# MCU_CTRL_MMR0_CFG0 register map
Vendor: Texas Instruments
Registers are 32-bit, read-write, reset 0x0 unless marked. A register's access mark holds for its fields unless they carry their own. Offsets are as the file gives them; [hi:lo] are bit positions; lines under a group give offsets from that group; {n}, {i} and the like mark numbered series.

## MCU_CTRL_MMR0_CFG0 (part 2 of 3)
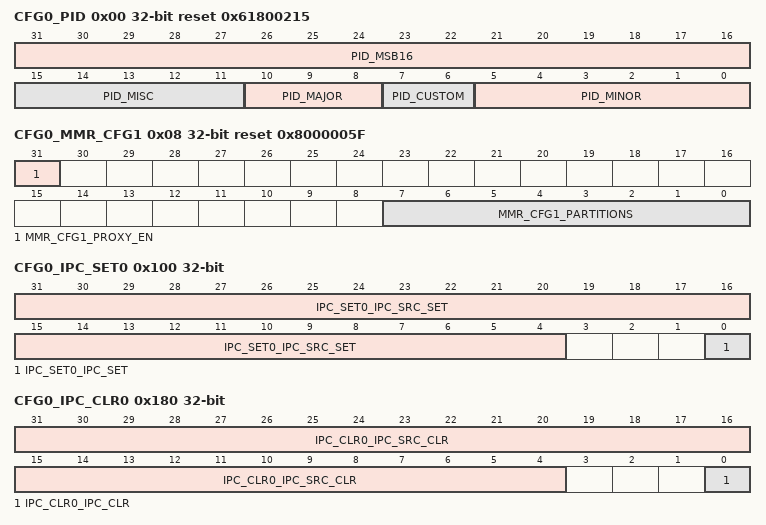
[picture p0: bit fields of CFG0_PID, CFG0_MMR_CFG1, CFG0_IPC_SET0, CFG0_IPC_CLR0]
0x00 CFG0_PID ro reset 0x61800215
  [31:16] PID_MSB16, [15:11] PID_MISC, [10:8] PID_MAJOR, [7:6] PID_CUSTOM, [5:0] PID_MINOR
0x08 CFG0_MMR_CFG1 ro reset 0x8000005F
  [31] MMR_CFG1_PROXY_EN — Proxy addressing activated
  [7:0] MMR_CFG1_PARTITIONS — Indicates present partitions
0x100 CFG0_IPC_SET0 access not given
  [31:4] IPC_SET0_IPC_SRC_SET — Read returns 0 Write: 0 - No effect 1 - Sets both corresponding IPC_CLR and the IPC_SET bits (access R/W1TS)
  [0] IPC_SET0_IPC_SET — Read returns 0 Write: 0 - No effect 1 - Sets both corresponding IPC_CLR and the IPC_SET bits (access R/W1TS)
0x180 CFG0_IPC_CLR0 access not given
  [31:4] IPC_CLR0_IPC_SRC_CLR — Read returns current value Write: 0 - No effect 1 - Clears both corresponding IPC_CLR and the IPC_SET bits (access R/W1TC)
  [0] IPC_CLR0_IPC_CLR — Read returns current value Write: 0 - No effect 1 - Clears both corresponding IPC_CLR and the IPC_SET bits (access R/W1TC)
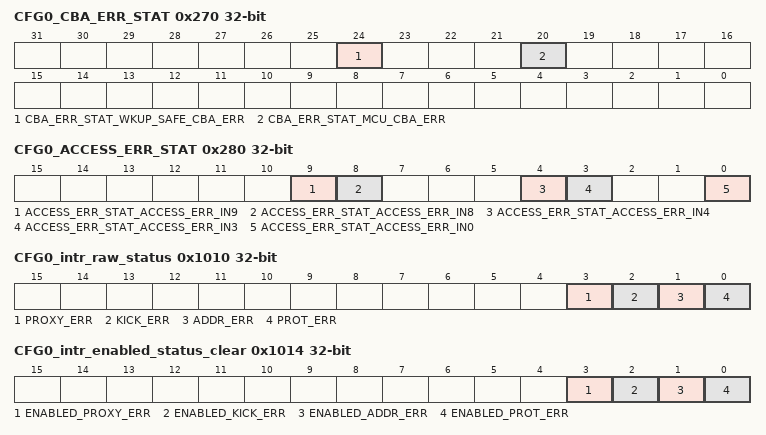
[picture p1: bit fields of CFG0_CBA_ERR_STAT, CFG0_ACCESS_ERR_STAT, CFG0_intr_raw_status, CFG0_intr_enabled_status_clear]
0x270 CFG0_CBA_ERR_STAT ro
  [24] CBA_ERR_STAT_WKUP_SAFE_CBA_ERR — Access Error from Wkup Safe CBASS Field values (others are reserved): 1'b0 - INACTIVE 1'b1 - ACTIVE
  [20] CBA_ERR_STAT_MCU_CBA_ERR — Access Error from MCU CBASS Field values (others are reserved): 1'b0 - INACTIVE 1'b1 - ACTIVE
0x280 CFG0_ACCESS_ERR_STAT ro
  [9] ACCESS_ERR_STAT_ACCESS_ERR_IN9 — Access Error From MCU_PADCFG_CTRL0 MMR Field values (others are reserved): 1'b0 - INACTIVE 1'b1 - ACTIVE
  [8] ACCESS_ERR_STAT_ACCESS_ERR_IN8 — Access Error From WKUP_CTRL_MMR1 Field values (others are reserved): 1'b0 - INACTIVE 1'b1 - ACTIVE
  [4] ACCESS_ERR_STAT_ACCESS_ERR_IN4 — Access Error From PADCFG_CTRL0 MMR Field values (others are reserved): 1'b0 - INACTIVE 1'b1 - ACTIVE
  [3] ACCESS_ERR_STAT_ACCESS_ERR_IN3 — Access Error From CTRL_MMR0 Field values (others are reserved): 1'b0 - INACTIVE 1'b1 - ACTIVE
  [0] ACCESS_ERR_STAT_ACCESS_ERR_IN0 — Access Error From WKUP_CTRL_MMR0 Field values (others are reserved): 1'b0 - INACTIVE 1'b1 - ACTIVE
{0x1008+0x4000*i} CFG0_LOCK{i}_KICK0 (i=0..4)
  [31:0] LOCK{i}_KICK0 — - KICK0 component
{0x100C+0x4000*i} CFG0_LOCK{i}_KICK1 (i=0..4)
  [31:0] LOCK{i}_KICK1 — - KICK1 component
0x1010 CFG0_intr_raw_status access not given
  [3] PROXY_ERR — Proxy0 access violation error. Raw status is read. Write a 1 to set the status. Writing a 0 has no effect. (access R/W1TS)
  [2] KICK_ERR — Kick access violation error. Raw status is read. Write a 1 to set the status. Writing a 0 has no effect. (access R/W1TS)
  [1] ADDR_ERR — Addressing violation error. Raw status is read. Write a 1 to set the status. Writing a 0 has no effect. (access R/W1TS)
  [0] PROT_ERR — Protection violation error. Raw status is read. Write a 1 to set the status. Writing a 0 has no effect. (access R/W1TS)
0x1014 CFG0_intr_enabled_status_clear access not given
  [3] ENABLED_PROXY_ERR — Proxy0 access violation error. Enabled status is read. Write a 1 to clear the status. Writing a 0 has no effect. (access R/W1TC)
  [2] ENABLED_KICK_ERR — Kick access violation error. Enabled status is read. Write a 1 to clear the status. Writing a 0 has no effect. (access R/W1TC)
  [1] ENABLED_ADDR_ERR — Addressing violation error. Enabled status is read. Write a 1 to clear the status. Writing a 0 has no effect. (access R/W1TC)
  [0] ENABLED_PROT_ERR — Protection violation error. Enabled status is read. Write a 1 to clear the status. Writing a 0 has no effect. (access R/W1TC)
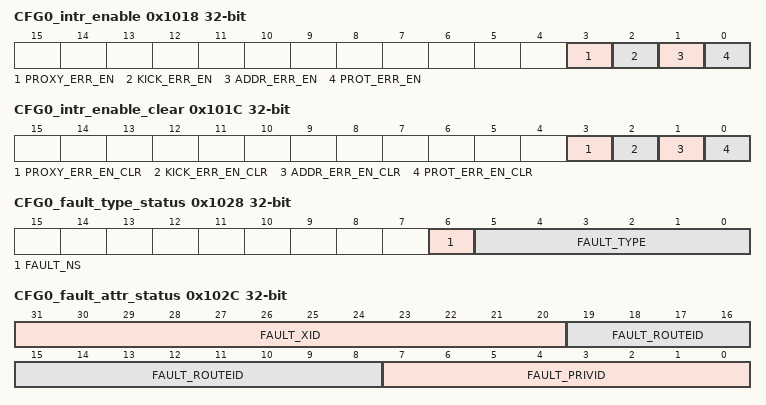
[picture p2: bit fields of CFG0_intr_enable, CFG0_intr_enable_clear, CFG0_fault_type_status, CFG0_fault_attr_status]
0x1018 CFG0_intr_enable access not given
  [3] PROXY_ERR_EN — Proxy0 access violation error enable. Write a 1 to set the enable. Writing a 0 has no effect. (access R/W1TS)
  [2] KICK_ERR_EN — Kick access violation error enable. Write a 1 to set the enable. Writing a 0 has no effect. (access R/W1TS)
  [1] ADDR_ERR_EN — Addressing violation error enable. Write a 1 to set the enable. Writing a 0 has no effect. (access R/W1TS)
  [0] PROT_ERR_EN — Protection violation error enable. Write a 1 to set the enable. Writing a 0 has no effect. (access R/W1TS)
0x101C CFG0_intr_enable_clear access not given
  [3] PROXY_ERR_EN_CLR — Proxy0 access violation error enable clear. Write a 1 to clear the enable. Writing a 0 has no effect. (access R/W1TC)
  [2] KICK_ERR_EN_CLR — Kick access violation error enable clear. Write a 1 to clear the enable. Writing a 0 has no effect. (access R/W1TC)
  [1] ADDR_ERR_EN_CLR — Addressing violation error enable clear. Write a 1 to clear the enable. Writing a 0 has no effect. (access R/W1TC)
  [0] PROT_ERR_EN_CLR — Protection violation error enable clear. Write a 1 to clear the enable. Writing a 0 has no effect. (access R/W1TC)
0x1020 CFG0_eoi
  [7:0] EOI_VECTOR — EOI vector value. Write this with interrupt distribution value in the chip.
0x1024 CFG0_fault_address ro
  [31:0] FAULT_ADDR — Fault Address.
0x1028 CFG0_fault_type_status ro
  [6] FAULT_NS — Non-secure access.
  [5:0] FAULT_TYPE — Fault Type 10_0000 = Supervisor read fault - priv = 1 dir = 1 dtype != 1 01_0000 = Supervisor write fault - priv = 1 dir = 0 00_1000 = Supervisor execute fault - priv = 1 dir = 1 dtype = 1 00_0100 = User read fault - priv = 0 dir = 1 dtype = 1 00_0010 = User write fault - priv = 0 dir = 0 00_0001 = User execute fault - priv = 0 dir = 1 dtype = 1 00_0000 = No fault
0x102C CFG0_fault_attr_status ro
  [31:20] FAULT_XID — XID.
  [19:8] FAULT_ROUTEID — Route ID.
  [7:0] FAULT_PRIVID — Privilege ID.
0x1030 CFG0_fault_clear wo
  [0] FAULT_CLR — Fault clear. Writing a 1 clears the current fault. Writing a 0 has no effect.
{0x1100+4i} CFG0_CLAIMREG_P0_R{i}_READONLY ro (i=0..5)
  [31:0] CLAIMREG_P0_R{i}_READONLY — Claim bits for Partition 0
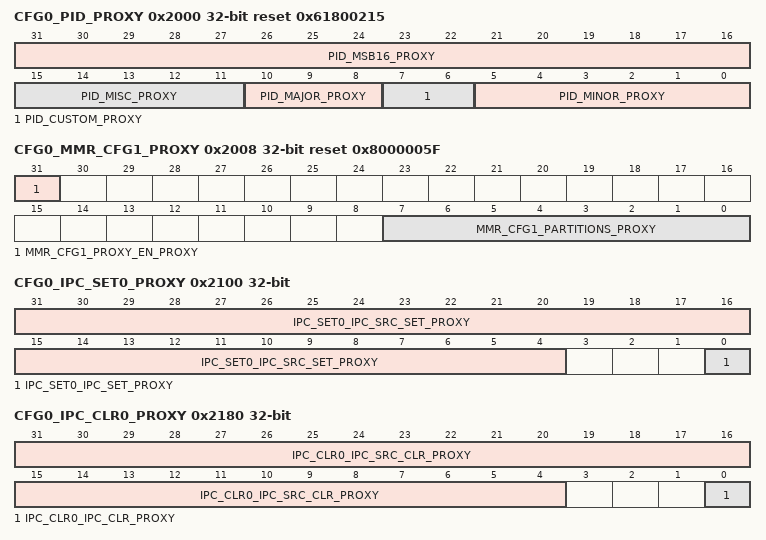
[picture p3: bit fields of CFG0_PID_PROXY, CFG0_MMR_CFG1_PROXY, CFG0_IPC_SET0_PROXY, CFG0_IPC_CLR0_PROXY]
0x2000 CFG0_PID_PROXY ro reset 0x61800215
  [31:16] PID_MSB16_PROXY, [15:11] PID_MISC_PROXY, [10:8] PID_MAJOR_PROXY, [7:6] PID_CUSTOM_PROXY, [5:0] PID_MINOR_PROXY
0x2008 CFG0_MMR_CFG1_PROXY ro reset 0x8000005F
  [31] MMR_CFG1_PROXY_EN_PROXY — Proxy addressing activated
  [7:0] MMR_CFG1_PARTITIONS_PROXY — Indicates present partitions
0x2100 CFG0_IPC_SET0_PROXY access not given
  [31:4] IPC_SET0_IPC_SRC_SET_PROXY — Read returns 0 Write: 0 - No effect 1 - Sets both corresponding IPC_CLR and the IPC_SET bits (access R/W1TS)
  [0] IPC_SET0_IPC_SET_PROXY — Read returns 0 Write: 0 - No effect 1 - Sets both corresponding IPC_CLR and the IPC_SET bits (access R/W1TS)
0x2180 CFG0_IPC_CLR0_PROXY access not given
  [31:4] IPC_CLR0_IPC_SRC_CLR_PROXY — Read returns current value Write: 0 - No effect 1 - Clears both corresponding IPC_CLR and the IPC_SET bits (access R/W1TC)
  [0] IPC_CLR0_IPC_CLR_PROXY — Read returns current value Write: 0 - No effect 1 - Clears both corresponding IPC_CLR and the IPC_SET bits (access R/W1TC)
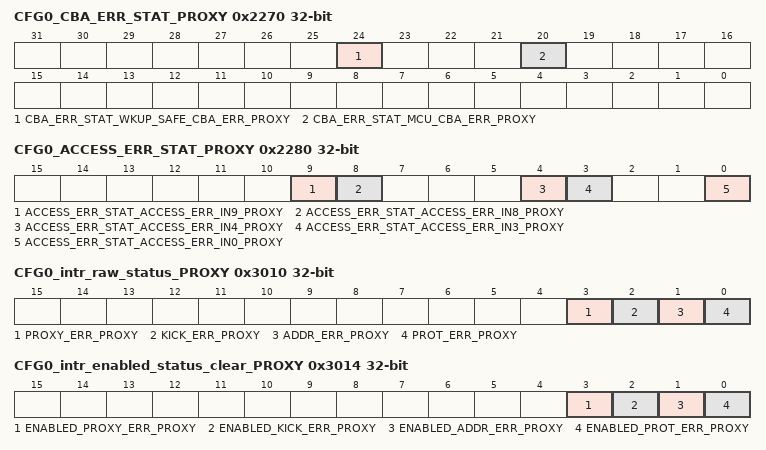
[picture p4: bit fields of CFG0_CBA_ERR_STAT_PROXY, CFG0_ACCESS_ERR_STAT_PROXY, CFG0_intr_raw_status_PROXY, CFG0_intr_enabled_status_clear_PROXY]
0x2270 CFG0_CBA_ERR_STAT_PROXY ro
  [24] CBA_ERR_STAT_WKUP_SAFE_CBA_ERR_PROXY — Access Error from Wkup Safe CBASS Field values (others are reserved): 1'b0 - INACTIVE 1'b1 - ACTIVE
  [20] CBA_ERR_STAT_MCU_CBA_ERR_PROXY — Access Error from MCU CBASS Field values (others are reserved): 1'b0 - INACTIVE 1'b1 - ACTIVE
0x2280 CFG0_ACCESS_ERR_STAT_PROXY ro
  [9] ACCESS_ERR_STAT_ACCESS_ERR_IN9_PROXY — Access Error From MCU_PADCFG_CTRL0 MMR Field values (others are reserved): 1'b0 - INACTIVE 1'b1 - ACTIVE
  [8] ACCESS_ERR_STAT_ACCESS_ERR_IN8_PROXY — Access Error From WKUP_CTRL_MMR1 Field values (others are reserved): 1'b0 - INACTIVE 1'b1 - ACTIVE
  [4] ACCESS_ERR_STAT_ACCESS_ERR_IN4_PROXY — Access Error From PADCFG_CTRL0 MMR Field values (others are reserved): 1'b0 - INACTIVE 1'b1 - ACTIVE
  [3] ACCESS_ERR_STAT_ACCESS_ERR_IN3_PROXY — Access Error From CTRL_MMR0 Field values (others are reserved): 1'b0 - INACTIVE 1'b1 - ACTIVE
  [0] ACCESS_ERR_STAT_ACCESS_ERR_IN0_PROXY — Access Error From WKUP_CTRL_MMR0 Field values (others are reserved): 1'b0 - INACTIVE 1'b1 - ACTIVE
{0x3008+0x4000*i} CFG0_LOCK{i}_KICK0_PROXY (i=0..4)
  [31:0] LOCK{i}_KICK0_PROXY — - KICK0 component
{0x300C+0x4000*i} CFG0_LOCK{i}_KICK1_PROXY (i=0..4)
  [31:0] LOCK{i}_KICK1_PROXY — - KICK1 component
0x3010 CFG0_intr_raw_status_PROXY access not given
  [3] PROXY_ERR_PROXY — Proxy0 access violation error. Raw status is read. Write a 1 to set the status. Writing a 0 has no effect. (access R/W1TS)
  [2] KICK_ERR_PROXY — Kick access violation error. Raw status is read. Write a 1 to set the status. Writing a 0 has no effect. (access R/W1TS)
  [1] ADDR_ERR_PROXY — Addressing violation error. Raw status is read. Write a 1 to set the status. Writing a 0 has no effect. (access R/W1TS)
  [0] PROT_ERR_PROXY — Protection violation error. Raw status is read. Write a 1 to set the status. Writing a 0 has no effect. (access R/W1TS)
0x3014 CFG0_intr_enabled_status_clear_PROXY access not given
  [3] ENABLED_PROXY_ERR_PROXY — Proxy0 access violation error. Enabled status is read. Write a 1 to clear the status. Writing a 0 has no effect. (access R/W1TC)
  [2] ENABLED_KICK_ERR_PROXY — Kick access violation error. Enabled status is read. Write a 1 to clear the status. Writing a 0 has no effect. (access R/W1TC)
  [1] ENABLED_ADDR_ERR_PROXY — Addressing violation error. Enabled status is read. Write a 1 to clear the status. Writing a 0 has no effect. (access R/W1TC)
  [0] ENABLED_PROT_ERR_PROXY — Protection violation error. Enabled status is read. Write a 1 to clear the status. Writing a 0 has no effect. (access R/W1TC)
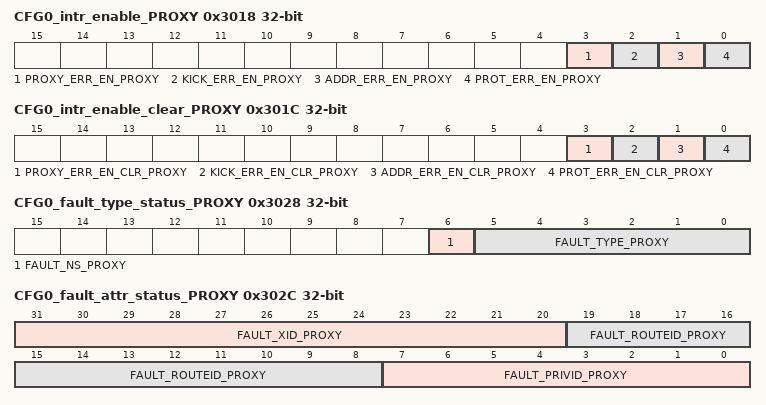
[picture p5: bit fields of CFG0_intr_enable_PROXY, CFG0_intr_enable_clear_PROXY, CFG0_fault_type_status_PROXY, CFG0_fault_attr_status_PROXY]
0x3018 CFG0_intr_enable_PROXY access not given
  [3] PROXY_ERR_EN_PROXY — Proxy0 access violation error enable. Write a 1 to set the enable. Writing a 0 has no effect. (access R/W1TS)
  [2] KICK_ERR_EN_PROXY — Kick access violation error enable. Write a 1 to set the enable. Writing a 0 has no effect. (access R/W1TS)
  [1] ADDR_ERR_EN_PROXY — Addressing violation error enable. Write a 1 to set the enable. Writing a 0 has no effect. (access R/W1TS)
  [0] PROT_ERR_EN_PROXY — Protection violation error enable. Write a 1 to set the enable. Writing a 0 has no effect. (access R/W1TS)
0x301C CFG0_intr_enable_clear_PROXY access not given
  [3] PROXY_ERR_EN_CLR_PROXY — Proxy0 access violation error enable clear. Write a 1 to clear the enable. Writing a 0 has no effect. (access R/W1TC)
  [2] KICK_ERR_EN_CLR_PROXY — Kick access violation error enable clear. Write a 1 to clear the enable. Writing a 0 has no effect. (access R/W1TC)
  [1] ADDR_ERR_EN_CLR_PROXY — Addressing violation error enable clear. Write a 1 to clear the enable. Writing a 0 has no effect. (access R/W1TC)
  [0] PROT_ERR_EN_CLR_PROXY — Protection violation error enable clear. Write a 1 to clear the enable. Writing a 0 has no effect. (access R/W1TC)
0x3020 CFG0_eoi_PROXY
  [7:0] EOI_VECTOR_PROXY — EOI vector value. Write this with interrupt distribution value in the chip.
0x3024 CFG0_fault_address_PROXY ro
  [31:0] FAULT_ADDR_PROXY — Fault Address.
0x3028 CFG0_fault_type_status_PROXY ro
  [6] FAULT_NS_PROXY — Non-secure access.
  [5:0] FAULT_TYPE_PROXY — Fault Type 10_0000 = Supervisor read fault - priv = 1 dir = 1 dtype != 1 01_0000 = Supervisor write fault - priv = 1 dir = 0 00_1000 = Supervisor execute fault - priv = 1 dir = 1 dtype = 1 00_0100 = User read fault - priv = 0 dir = 1 dtype = 1 00_0010 = User write fault - priv = 0 dir = 0 00_0001 = User execute fault - priv = 0 dir = 1 dtype = 1 00_0000 = No fault
0x302C CFG0_fault_attr_status_PROXY ro
  [31:20] FAULT_XID_PROXY — XID.
  [19:8] FAULT_ROUTEID_PROXY — Route ID.
  [7:0] FAULT_PRIVID_PROXY — Privilege ID.
0x3030 CFG0_fault_clear_PROXY wo
  [0] FAULT_CLR_PROXY — Fault clear. Writing a 1 clears the current fault. Writing a 0 has no effect.
{0x3100+4i} CFG0_CLAIMREG_P0_R{i} (i=0..5)
  [31:0] CLAIMREG_P0_R{i} — Claim bits for Partition 0
0x4020 CFG0_MCU_GPIO_CTRL
  [0] MCU_GPIO_CTRL_WAKEN — Determines whether or not MCU_GPIO clock is stopped by its LPSC. Preventing the clock stop allows the MCU_GPIO to provide a wakeup event. Field values (others are reserved): 1'b0 - WAKEUP_DISABLED 1'b1 - WAKEUP_ENABLED
{0x4080+4i} CFG0_DBOUNCE_CFG{i} (i=1..6)
  [5:0] DBOUNCE_CFG{i}_DB_CFG — Configures the debounce period used for I/Os with PADCONFIGx_DEBOUNCE_SEL = {i}. Debounce period is specified as a number of CLK0 or CLK1 clock cycles. For all inputs except EQEP inputs, CLK0 is CLK_32K_RC and CLK1 is HFOSC0_CLKOUT. For EQEP, faster clocks are used. CLK0 is HFOSC0_CLKOUT and CLK1 is MAIN_SYSCLK0/2. Field values (others are reserved): 6'b000000 - BYPASS 6'b000001 - DB_64_CLK0 6'b000010 - DB_96_CLK0 6'b000011 - DB_128_CLK0 6'b000100 - DB_160_CLK0 6'b000101 - DB_192_CLK0 6'b000110 - DB_224_CLK0 6'b000111 - DB_256_CLK0 6'b001000 - DB_288_CLK0 6'b001001 - DB_320_CLK0 6'b001010 - DB_352_CLK0 6'b001011 - DB_384_CLK0 6'b001100 - DB_416_CLK0 6'b001101 - DB_448_CLK0 6'b001110 - DB_480_CLK0 6'b001111 - DB_512_CLK0 6'b010000 - DB_544_CLK0 6'b010001 - DB_576_CLK0 6'b010010 - DB_608_CLK0 6'b010011 - DB_640_CLK0 6'b010100 - DB_672_CLK0 6'b010101 - DB_704_CLK0 6'b010110 - DB_512_CLK0 6'b010111 - DB_1024_CLK0 6'b011000 - DB_1536_CLK0 6'b011001 - DB_2048_CLK0 6'b011010 - DB_2560_CLK0 6'b011011 - DB_3072_CLK0 6'b011100 - DB_3584_CLK0 6'b011101 - DB_4096_CLK0 6'b011110 - DB_4608_CLK0 6'b011111 - DB_5120_CLK0 6'b100000 - DB_1_CLK1 6'b100001 - DB_2_CLK1 6'b100010 - DB_3_CLK1 6'b100011 - DB_4_CLK1 6'b100100 - DB_5_CLK1 6'b100101 - DB_6_CLK1 6'b100110 - DB_7_CLK1 6'b100111 - DB_8_CLK1 6'b101000 - DB_9_CLK1 6'b101001 - DB_10_CLK1 6'b101010 - DB_11_CLK1 6'b101011 - DB_12_CLK1 6'b101100 - DB_13_CLK1 6'b101101 - DB_14_CLK1 6'b101110 - DB_15_CLK1 6'b101111 - DB_16_CLK1 6'b110000 - DB_17_CLK1 6'b110001 - DB_18_CLK1 6'b110010 - DB_19_CLK1 6'b110011 - DB_20_CLK1 6'b110100 - DB_21_CLK1 6'b110101 - DB_22_CLK1 6'b110110 - DB_512_CLK1 6'b110111 - DB_1024_CLK1 6'b111000 - DB_1536_CLK1 6'b111001 - DB_2048_CLK1 6'b111010 - DB_2560_CLK1 6'b111011 - DB_3072_CLK1 6'b111100 - DB_3584_CLK1 6'b111101 - DB_4096_CLK1 6'b111110 - DB_4608_CLK1 6'b111111 - DB_5120_CLK1
0x40A0 CFG0_TEMP_DIODE_TRIM ro
  [13:0] TEMP_DIODE_TRIM_TRIM — Trimmed value of diode non-ideality factor (n), starting from 100th place decimal and going down
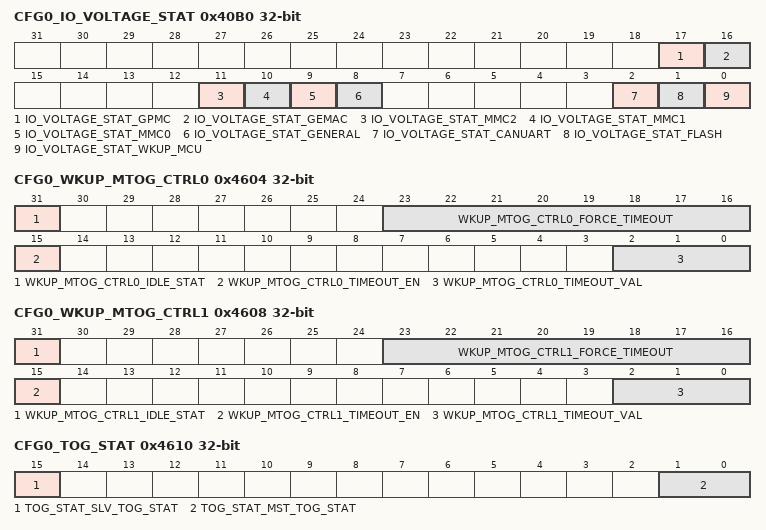
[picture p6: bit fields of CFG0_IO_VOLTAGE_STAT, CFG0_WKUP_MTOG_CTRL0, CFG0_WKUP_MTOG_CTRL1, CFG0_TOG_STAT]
0x40B0 CFG0_IO_VOLTAGE_STAT ro
  [17] IO_VOLTAGE_STAT_GPMC — Detected voltage for GPMC I/O group (VDDSHV3) Field values (others are reserved): 1'b0 - IOGROUP_3P3V 1'b1 - IOGROUP_1P8V
  [16] IO_VOLTAGE_STAT_GEMAC — Detected voltage for the GEMAC I/O group (VDDSHV2) Field values (others are reserved): 1'b0 - IOGROUP_3P3V 1'b1 - IOGROUP_1P8V
  [11] IO_VOLTAGE_STAT_MMC2 — Detected voltage for the MMC2 I/O group (VDDSHV6) Field values (others are reserved): 1'b0 - IOGROUP_3P3V 1'b1 - IOGROUP_1P8V
  [10] IO_VOLTAGE_STAT_MMC1 — Detected voltage for the MMC1 I/O group (VDDSHV5) Field values (others are reserved): 1'b0 - IOGROUP_3P3V 1'b1 - IOGROUP_1P8V
  [9] IO_VOLTAGE_STAT_MMC0 — Detected voltage for the MMC0 I/O group (VDDSHV4) Field values (others are reserved): 1'b0 - IOGROUP_3P3V 1'b1 - IOGROUP_1P8V
  [8] IO_VOLTAGE_STAT_GENERAL — Detected voltage for the General I/O group (VDDSHV0) Field values (others are reserved): 1'b0 - IOGROUP_3P3V 1'b1 - IOGROUP_1P8V
  [2] IO_VOLTAGE_STAT_CANUART — Detected voltage for the CANUART I/O group (VDDSHV_WKUP) Field values (others are reserved): 1'b0 - IOGROUP_3P3V 1'b1 - IOGROUP_1P8V
  [1] IO_VOLTAGE_STAT_FLASH — Detected voltage for the Flash I/O group (VDDSHV1) Field values (others are reserved): 1'b0 - IOGROUP_3P3V 1'b1 - IOGROUP_1P8V
  [0] IO_VOLTAGE_STAT_WKUP_MCU — Detected voltage for the WKUP_MCU I/O group (VDDSHV_MCU) Field values (others are reserved): 1'b0 - IOGROUP_3P3V 1'b1 - IOGROUP_1P8V
0x4204 CFG0_MCU_TIMER1_CTRL
  [8] MCU_TIMER1_CTRL_CASCADE_EN — Activates cascading of TIMER1 to TIMER0 Field values (others are reserved): 1'b0 - CASCADE_DEACTIVATED 1'b1 - CASCADE_ACTIVATED
0x420C CFG0_MCU_TIMER3_CTRL
  [8] MCU_TIMER3_CTRL_CASCADE_EN — Activates cascading of TIMER3 to TIMER2 Field values (others are reserved): 1'b0 - CASCADE_DEACTIVATED 1'b1 - CASCADE_ACTIVATED
0x42E0 CFG0_MCU_I2C0_CTRL
  [0] MCU_I2C0_CTRL_HS_MCS_EN — HS Mode controller current source activate. When set, activates the current-source pull-up on the SCL output. Only one controller on the I2C bus should activate SCL current sourcing. Field values (others are reserved): 1'b0 - HS_MCS_INACTIVE 1'b1 - HS_MCS_ACTIVE
0x4604 CFG0_WKUP_MTOG_CTRL0 access per field
  [31] WKUP_MTOG_CTRL0_IDLE_STAT ro — Indicates the Gasket is Idle Field values (others are reserved): 1'b0 - BUSY 1'b1 - IDLE
  [23:16] WKUP_MTOG_CTRL0_FORCE_TIMEOUT rw — Force Timout This is a fault tolerant bitfield. Forces a flush of the interface transactions. This bitfield is only relevant if timeout_en=1. After forcing a timeout by writing the encoded value, the force_timeout and timeout_en bitfields mut be cleared to clear the timeout before re-enabling the gasket. Field values (others are reserved): 8'h00 - CLEAR_TIMEOUT 8'h95 - FORCE_TIMEOUT
  [15] WKUP_MTOG_CTRL0_TIMEOUT_EN rw — Activate Timeout Gasket Field values (others are reserved): 1'b0 - ACTIVE 1'b1 - INACTIVE
  [2:0] WKUP_MTOG_CTRL0_TIMEOUT_VAL rw — Gasket Timeout Value Selects the number of clock cycles before the interface is considered to have timed out Field values (others are reserved): 3'b000 - TO_1K_CYCLES 3'b001 - TO_4K_CYCLES 3'b010 - TO_16K_CYCLES 3'b011 - TO_64K_CYCLES 3'b100 - TO_256K_CYCLES 3'b101 - TO_1024K_CYCLES 3'b110 - TO_2048K_CYCLES 3'b111 - TO_4096K_CYCLES
0x4608 CFG0_WKUP_MTOG_CTRL1 access per field
  [31] WKUP_MTOG_CTRL1_IDLE_STAT ro — Indicates the Gasket is Idle Field values (others are reserved): 1'b0 - BUSY 1'b1 - IDLE
  [23:16] WKUP_MTOG_CTRL1_FORCE_TIMEOUT rw — Force Timout This is a fault tolerant bitfield. Forces a flush of the interface transactions. This bitfield is only relevant if timeout_en=1. After forcing a timeout by writing the encoded value, the force_timeout and timeout_en bitfields mut be cleared to clear the timeout before re-enabling the gasket. Field values (others are reserved): 8'h00 - CLEAR_TIMEOUT 8'h95 - FORCE_TIMEOUT
  [15] WKUP_MTOG_CTRL1_TIMEOUT_EN rw — Activate Timeout Gasket Field values (others are reserved): 1'b0 - ACTIVE 1'b1 - INACTIVE
  [2:0] WKUP_MTOG_CTRL1_TIMEOUT_VAL rw — Gasket Timeout Value Selects the number of clock cycles before the interface is considered to have timed out Field values (others are reserved): 3'b000 - TO_1K_CYCLES 3'b001 - TO_4K_CYCLES 3'b010 - TO_16K_CYCLES 3'b011 - TO_64K_CYCLES 3'b100 - TO_256K_CYCLES 3'b101 - TO_1024K_CYCLES 3'b110 - TO_2048K_CYCLES 3'b111 - TO_4096K_CYCLES
0x4610 CFG0_TOG_STAT ro
  [15] TOG_STAT_SLV_TOG_STAT — Error Status of Target Timeout Gaskets Field values (others are reserved): 1'b0 - NO_ERROR 1'b1 - MCU_TIMEOUT0
  [1:0] TOG_STAT_MST_TOG_STAT — Error Status of Initiator Timeout Gaskets Field values (others are reserved): 2'b00 - NO_ERROR 2'b01 - WKUP_TIMEOUT1 2'b10 - WKUP_TIMEOUT0 2'b11 - WKUP_TIMEOUT0_AND_WKUP_TIMEOUT1
{0x5100+4i} CFG0_CLAIMREG_P1_R{i}_READONLY ro (i=0..12)
  [31:0] CLAIMREG_P1_R{i}_READONLY — Claim bits for Partition 1
0x6020 CFG0_MCU_GPIO_CTRL_PROXY
  [0] MCU_GPIO_CTRL_WAKEN_PROXY — Determines whether or not MCU_GPIO clock is stopped by its LPSC. Preventing the clock stop allows the MCU_GPIO to provide a wakeup event. Field values (others are reserved): 1'b0 - WAKEUP_DISABLED 1'b1 - WAKEUP_ENABLED
{0x6080+4i} CFG0_DBOUNCE_CFG{i}_PROXY (i=1..6)
  [5:0] DBOUNCE_CFG{i}_DB_CFG_PROXY — Configures the debounce period used for I/Os with PADCONFIGx_DEBOUNCE_SEL = {i}. Debounce period is specified as a number of CLK0 or CLK1 clock cycles. For all inputs except EQEP inputs, CLK0 is CLK_32K_RC and CLK1 is HFOSC0_CLKOUT. For EQEP, faster clocks are used. CLK0 is HFOSC0_CLKOUT and CLK1 is MAIN_SYSCLK0/2. Field values (others are reserved): 6'b000000 - BYPASS 6'b000001 - DB_64_CLK0 6'b000010 - DB_96_CLK0 6'b000011 - DB_128_CLK0 6'b000100 - DB_160_CLK0 6'b000101 - DB_192_CLK0 6'b000110 - DB_224_CLK0 6'b000111 - DB_256_CLK0 6'b001000 - DB_288_CLK0 6'b001001 - DB_320_CLK0 6'b001010 - DB_352_CLK0 6'b001011 - DB_384_CLK0 6'b001100 - DB_416_CLK0 6'b001101 - DB_448_CLK0 6'b001110 - DB_480_CLK0 6'b001111 - DB_512_CLK0 6'b010000 - DB_544_CLK0 6'b010001 - DB_576_CLK0 6'b010010 - DB_608_CLK0 6'b010011 - DB_640_CLK0 6'b010100 - DB_672_CLK0 6'b010101 - DB_704_CLK0 6'b010110 - DB_512_CLK0 6'b010111 - DB_1024_CLK0 6'b011000 - DB_1536_CLK0 6'b011001 - DB_2048_CLK0 6'b011010 - DB_2560_CLK0 6'b011011 - DB_3072_CLK0 6'b011100 - DB_3584_CLK0 6'b011101 - DB_4096_CLK0 6'b011110 - DB_4608_CLK0 6'b011111 - DB_5120_CLK0 6'b100000 - DB_1_CLK1 6'b100001 - DB_2_CLK1 6'b100010 - DB_3_CLK1 6'b100011 - DB_4_CLK1 6'b100100 - DB_5_CLK1 6'b100101 - DB_6_CLK1 6'b100110 - DB_7_CLK1 6'b100111 - DB_8_CLK1 6'b101000 - DB_9_CLK1 6'b101001 - DB_10_CLK1 6'b101010 - DB_11_CLK1 6'b101011 - DB_12_CLK1 6'b101100 - DB_13_CLK1 6'b101101 - DB_14_CLK1 6'b101110 - DB_15_CLK1 6'b101111 - DB_16_CLK1 6'b110000 - DB_17_CLK1 6'b110001 - DB_18_CLK1 6'b110010 - DB_19_CLK1 6'b110011 - DB_20_CLK1 6'b110100 - DB_21_CLK1 6'b110101 - DB_22_CLK1 6'b110110 - DB_512_CLK1 6'b110111 - DB_1024_CLK1 6'b111000 - DB_1536_CLK1 6'b111001 - DB_2048_CLK1 6'b111010 - DB_2560_CLK1 6'b111011 - DB_3072_CLK1 6'b111100 - DB_3584_CLK1 6'b111101 - DB_4096_CLK1 6'b111110 - DB_4608_CLK1 6'b111111 - DB_5120_CLK1
0x60A0 CFG0_TEMP_DIODE_TRIM_PROXY ro
  [13:0] TEMP_DIODE_TRIM_TRIM_PROXY — Trimmed value of diode non-ideality factor (n), starting from 100th place decimal and going down
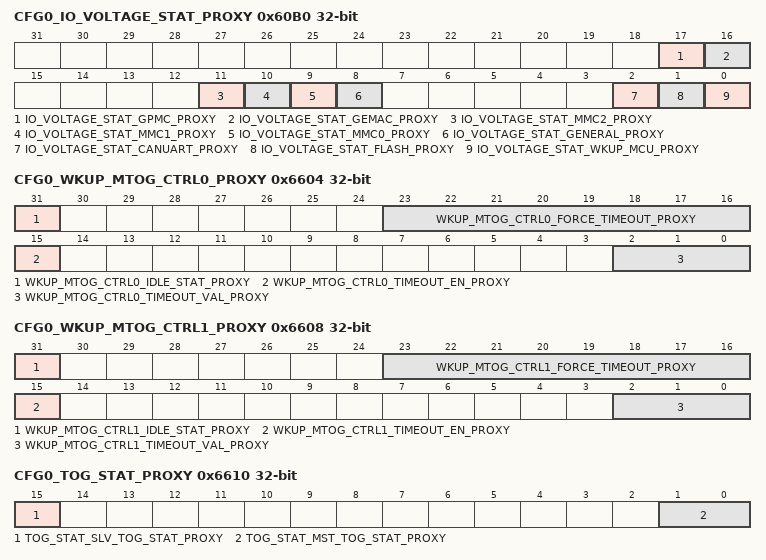
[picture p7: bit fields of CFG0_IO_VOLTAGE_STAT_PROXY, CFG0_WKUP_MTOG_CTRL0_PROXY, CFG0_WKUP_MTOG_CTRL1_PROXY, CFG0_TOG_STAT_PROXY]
0x60B0 CFG0_IO_VOLTAGE_STAT_PROXY ro
  [17] IO_VOLTAGE_STAT_GPMC_PROXY — Detected voltage for GPMC I/O group (VDDSHV3) Field values (others are reserved): 1'b0 - IOGROUP_3P3V 1'b1 - IOGROUP_1P8V
  [16] IO_VOLTAGE_STAT_GEMAC_PROXY — Detected voltage for the GEMAC I/O group (VDDSHV2) Field values (others are reserved): 1'b0 - IOGROUP_3P3V 1'b1 - IOGROUP_1P8V
  [11] IO_VOLTAGE_STAT_MMC2_PROXY — Detected voltage for the MMC2 I/O group (VDDSHV6) Field values (others are reserved): 1'b0 - IOGROUP_3P3V 1'b1 - IOGROUP_1P8V
  [10] IO_VOLTAGE_STAT_MMC1_PROXY — Detected voltage for the MMC1 I/O group (VDDSHV5) Field values (others are reserved): 1'b0 - IOGROUP_3P3V 1'b1 - IOGROUP_1P8V
  [9] IO_VOLTAGE_STAT_MMC0_PROXY — Detected voltage for the MMC0 I/O group (VDDSHV4) Field values (others are reserved): 1'b0 - IOGROUP_3P3V 1'b1 - IOGROUP_1P8V
  [8] IO_VOLTAGE_STAT_GENERAL_PROXY — Detected voltage for the General I/O group (VDDSHV0) Field values (others are reserved): 1'b0 - IOGROUP_3P3V 1'b1 - IOGROUP_1P8V
  [2] IO_VOLTAGE_STAT_CANUART_PROXY — Detected voltage for the CANUART I/O group (VDDSHV_WKUP) Field values (others are reserved): 1'b0 - IOGROUP_3P3V 1'b1 - IOGROUP_1P8V
  [1] IO_VOLTAGE_STAT_FLASH_PROXY — Detected voltage for the Flash I/O group (VDDSHV1) Field values (others are reserved): 1'b0 - IOGROUP_3P3V 1'b1 - IOGROUP_1P8V
  [0] IO_VOLTAGE_STAT_WKUP_MCU_PROXY — Detected voltage for the WKUP_MCU I/O group (VDDSHV_MCU) Field values (others are reserved): 1'b0 - IOGROUP_3P3V 1'b1 - IOGROUP_1P8V
0x6204 CFG0_MCU_TIMER1_CTRL_PROXY
  [8] MCU_TIMER1_CTRL_CASCADE_EN_PROXY — Activates cascading of TIMER1 to TIMER0 Field values (others are reserved): 1'b0 - CASCADE_DEACTIVATED 1'b1 - CASCADE_ACTIVATED
0x620C CFG0_MCU_TIMER3_CTRL_PROXY
  [8] MCU_TIMER3_CTRL_CASCADE_EN_PROXY — Activates cascading of TIMER3 to TIMER2 Field values (others are reserved): 1'b0 - CASCADE_DEACTIVATED 1'b1 - CASCADE_ACTIVATED
0x62E0 CFG0_MCU_I2C0_CTRL_PROXY
  [0] MCU_I2C0_CTRL_HS_MCS_EN_PROXY — HS Mode controller current source activate. When set, activates the current-source pull-up on the SCL output. Only one controller on the I2C bus should activate SCL current sourcing. Field values (others are reserved): 1'b0 - HS_MCS_INACTIVE 1'b1 - HS_MCS_ACTIVE
0x6604 CFG0_WKUP_MTOG_CTRL0_PROXY access per field
  [31] WKUP_MTOG_CTRL0_IDLE_STAT_PROXY ro — Indicates the Gasket is Idle Field values (others are reserved): 1'b0 - BUSY 1'b1 - IDLE
  [23:16] WKUP_MTOG_CTRL0_FORCE_TIMEOUT_PROXY rw — Force Timout This is a fault tolerant bitfield. Forces a flush of the interface transactions. This bitfield is only relevant if timeout_en=1. After forcing a timeout by writing the encoded value, the force_timeout and timeout_en bitfields mut be cleared to clear the timeout before re-enabling the gasket. Field values (others are reserved): 8'h00 - CLEAR_TIMEOUT 8'h95 - FORCE_TIMEOUT
  [15] WKUP_MTOG_CTRL0_TIMEOUT_EN_PROXY rw — Activate Timeout Gasket Field values (others are reserved): 1'b0 - ACTIVE 1'b1 - INACTIVE
  [2:0] WKUP_MTOG_CTRL0_TIMEOUT_VAL_PROXY rw — Gasket Timeout Value Selects the number of clock cycles before the interface is considered to have timed out Field values (others are reserved): 3'b000 - TO_1K_CYCLES 3'b001 - TO_4K_CYCLES 3'b010 - TO_16K_CYCLES 3'b011 - TO_64K_CYCLES 3'b100 - TO_256K_CYCLES 3'b101 - TO_1024K_CYCLES 3'b110 - TO_2048K_CYCLES 3'b111 - TO_4096K_CYCLES
0x6608 CFG0_WKUP_MTOG_CTRL1_PROXY access per field
  [31] WKUP_MTOG_CTRL1_IDLE_STAT_PROXY ro — Indicates the Gasket is Idle Field values (others are reserved): 1'b0 - BUSY 1'b1 - IDLE
  [23:16] WKUP_MTOG_CTRL1_FORCE_TIMEOUT_PROXY rw — Force Timout This is a fault tolerant bitfield. Forces a flush of the interface transactions. This bitfield is only relevant if timeout_en=1. After forcing a timeout by writing the encoded value, the force_timeout and timeout_en bitfields mut be cleared to clear the timeout before re-enabling the gasket. Field values (others are reserved): 8'h00 - CLEAR_TIMEOUT 8'h95 - FORCE_TIMEOUT
  [15] WKUP_MTOG_CTRL1_TIMEOUT_EN_PROXY rw — Activate Timeout Gasket Field values (others are reserved): 1'b0 - ACTIVE 1'b1 - INACTIVE
  [2:0] WKUP_MTOG_CTRL1_TIMEOUT_VAL_PROXY rw — Gasket Timeout Value Selects the number of clock cycles before the interface is considered to have timed out Field values (others are reserved): 3'b000 - TO_1K_CYCLES 3'b001 - TO_4K_CYCLES 3'b010 - TO_16K_CYCLES 3'b011 - TO_64K_CYCLES 3'b100 - TO_256K_CYCLES 3'b101 - TO_1024K_CYCLES 3'b110 - TO_2048K_CYCLES 3'b111 - TO_4096K_CYCLES
0x6610 CFG0_TOG_STAT_PROXY ro
  [15] TOG_STAT_SLV_TOG_STAT_PROXY — Error Status of Target Timeout Gaskets Field values (others are reserved): 1'b0 - NO_ERROR 1'b1 - MCU_TIMEOUT0
  [1:0] TOG_STAT_MST_TOG_STAT_PROXY — Error Status of Initiator Timeout Gaskets Field values (others are reserved): 2'b00 - NO_ERROR 2'b01 - WKUP_TIMEOUT1 2'b10 - WKUP_TIMEOUT0 2'b11 - WKUP_TIMEOUT0_AND_WKUP_TIMEOUT1
{0x7100+4i} CFG0_CLAIMREG_P1_R{i} (i=0..12)
  [31:0] CLAIMREG_P1_R{i} — Claim bits for Partition 1
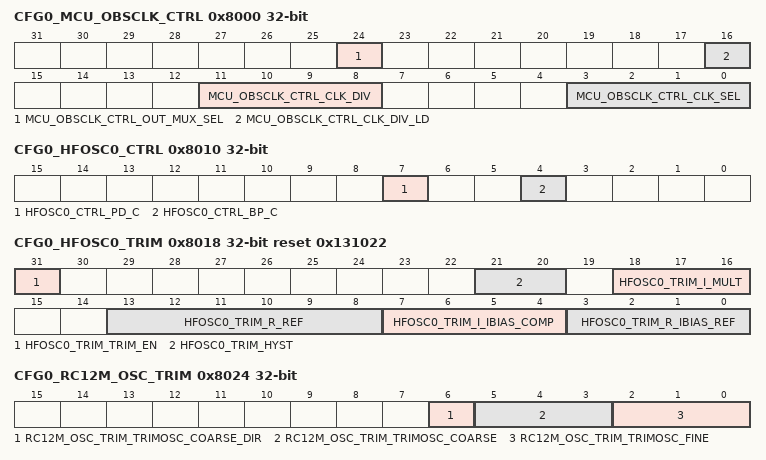
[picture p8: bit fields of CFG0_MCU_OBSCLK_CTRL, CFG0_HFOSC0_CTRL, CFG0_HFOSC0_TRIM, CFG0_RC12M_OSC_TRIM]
0x8000 CFG0_MCU_OBSCLK_CTRL
  [24] MCU_OBSCLK_CTRL_OUT_MUX_SEL — MCU_OBSCLK pin output mux selection. Note, HFOSC0_CLK is a direct output from the HFOSC0, distinct from HFOSC0_CLKOUT. Note, when HFOSC0_CLK is selected (1'b1) the MCU_OBSCLK_CTRL_clk_sel field must be programmed to 4'b0001. Field values (others are reserved): 1'b0 - CLK_DIV_OUT 1'b1 - HFOSC0_CLK (clk_sel must be OFF)
  [16] MCU_OBSCLK_CTRL_CLK_DIV_LD — Load the output divider value Writing 1 to this bit will generate a load pulse to load the OBSCLK divider value. This bit can be cleared but must not be set in the same write cycle in which the clk_div value is changed. Field values (others are reserved): 1'b0 - READY 1'b1 - LOAD
  [11:8] MCU_OBSCLK_CTRL_CLK_DIV — MCU_OBSCLK pin clock selection output divider Output clock is divided by clk_div+1
  [3:0] MCU_OBSCLK_CTRL_CLK_SEL — MCU_OBSCLK pin clock selection Field values (others are reserved): 4'b0000 - CLK_12M_RC 4'b0001 - OFF 4'b0010 - MCU_PLL0_HSDIV0_CLKOUT 4'b0011 - MCU_PLL0_HSDIV4_CLKOUT 4'b0100 - MCU_PLLCTRL_OBSCLK 4'b0101 - CLK_32K_RC 4'b0110 - HFOSC0_CLKOUT 4'b0111 - HFOSC0_CLKOUT_32K 4'b1000 - MCU_SYSCLK0 4'b1001 - DEVICE_CLKOUT_32K
0x8010 CFG0_HFOSC0_CTRL
  [7] HFOSC0_CTRL_PD_C — Oscillator powerdown control. Field values (others are reserved): 1'b0 - ACTIVE 1'b1 - POWERDOWN
  [4] HFOSC0_CTRL_BP_C — Must Write '0'
0x8018 CFG0_HFOSC0_TRIM reset 0x131022
  [31] HFOSC0_TRIM_TRIM_EN — Apply MMR values to OSC trim inputs instead of tie-offs Field values (others are reserved): 1'b0 - FIXED_TRIM 1'b1 - MMR_TRIM
  [21:20] HFOSC0_TRIM_HYST — Sets comparator hysterisis Field values (others are reserved): 2'b00 - NO_HYS 2'b01 - TYPE1_HYS 2'b10 - TYPE2_HYS 2'b11 - BOTH_TYPES_HYS
  [18:16] HFOSC0_TRIM_I_MULT — AGC AMP current multiplication gain Field values (others are reserved): 3'b000 - GAIN_0P250X 3'b001 - GAIN_0P375X 3'b010 - GAIN_0P500X 3'b011 - GAIN_0P625X 3'b100 - GAIN_0P750X 3'b101 - GAIN_0P875X 3'b110 - GAIN_1X 3'b111 - GAIN_1P250X
  [13:8] HFOSC0_TRIM_R_REF — Sets the AMP AGC bias current Field values (others are reserved): 6'b000000 - R_REF_4X 6'b001000 - R_REF_6X 6'b010000 - R_REF_8X 6'b011000 - R_REF_10X 6'b100000 - R_REF_12X 6'b101000 - R_REF_14X 6'b110000 - R_REF_16X 6'b111000 - R_REF_18X
  [7:4] HFOSC0_TRIM_I_IBIAS_COMP — Sets the COMP bias current Field values (others are reserved): 4'b0000 - I_BIAS_COMP_2P00X 4'b0001 - I_BIAS_COMP_2P25X 4'b0010 - I_BIAS_COMP_2P50X 4'b0011 - I_BIAS_COMP_2P75X 4'b0100 - I_BIAS_COMP__2P50X 4'b0101 - I_BIAS_COMP__2P75X 4'b0110 - I_BIAS_COMP_3P00X 4'b0111 - I_BIAS_COMP_3P25X 4'b1000 - I_BIAS_COMP__3P00X 4'b1001 - I_BIAS_COMP__3P25X 4'b1010 - I_BIAS_COMP_3P50X 4'b1011 - I_BIAS_COMP_3P75X 4'b1100 - I_BIAS_COMP_3P50X 4'b1101 - I_BIAS_COMP_3P75X 4'b1110 - I_BIAS_COMP_4P00X 4'b1111 - I_BIAS_COMP_4P25X
  [3:0] HFOSC0_TRIM_R_IBIAS_REF — Sets the base IBIAS reference Field values (others are reserved): 4'b0000 - IBIAS_REF_1X 4'b0001 - IBIAS_REF_5X 4'b0010 - IBIAS_REF_3X (Default) 4'b0011 - IBIAS_REF_7X
0x8020 CFG0_HFOSC0_STAT ro
  [0] HFOSC0_STAT_DS_ON_WFI_STAT — Reflects the status of Device Manager Request to Disable HFOSC0 when it enters the WFI state (DeepSleep Entry) Field values (others are reserved): 1'b0 - NO_DEEPSLEEP_REQUEST 1'b1 - DEEPSLEEP_REQUEST
0x8024 CFG0_RC12M_OSC_TRIM
  [6] RC12M_OSC_TRIM_TRIMOSC_COARSE_DIR — Coarse adjustment direction. Field values (others are reserved): 1'b0 - TRIM_FREQ_LOWER 1'b1 - TRIM_FREQ_HIGHER
  [5:3] RC12M_OSC_TRIM_TRIMOSC_COARSE — Coarse adjustment. Frequency is decreased or increased by 1.25 MHz per value based on the trimosc_coarse_dir value. Field values (others are reserved): 3'b000 - TRIM_0_MHZ 3'b001 - TRIM_1P25_MHZ 3'b010 - TRIM_2P50_MHZ 3'b011 - TRIM_3P75_MHZ 3'b100 - TRIM_4P00_MHZ 3'b101 - TRIM_5P25_MHZ 3'b110 - TRIM_6P50_MHZ 3'b111 - TRIM_7P75_MHZ
  [2:0] RC12M_OSC_TRIM_TRIMOSC_FINE — Fine adjustment. Decreases the frequency by 250 KHz per value. Field values (others are reserved): 3'b000 - TRIM_0_KHZ 3'b001 - TRIM_250_KHZ 3'b010 - TRIM_500_KHZ 3'b011 - TRIM_750_KHZ 3'b100 - TRIM_1000_KHZ 3'b101 - TRIM_1250_KHZ 3'b110 - TRIM_1500_KHZ 3'b111 - TRIM_1750_KHZ
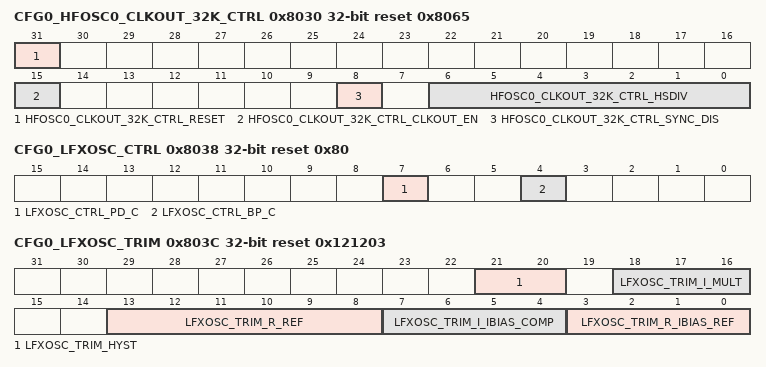
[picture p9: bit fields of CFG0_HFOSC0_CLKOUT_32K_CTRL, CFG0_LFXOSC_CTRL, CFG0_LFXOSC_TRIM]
0x8030 CFG0_HFOSC0_CLKOUT_32K_CTRL reset 0x8065
  [31] HFOSC0_CLKOUT_32K_CTRL_RESET — Asynchronous Divider Reset. Field values (others are reserved): 1'b0 - ACTIVE 1'b1 - RESET
  [15] HFOSC0_CLKOUT_32K_CTRL_CLKOUT_EN — HFOSC0_CLKOUT_32K output active Field values (others are reserved): 1'b0 - INACTIVE 1'b1 - ACTIVE
  [8] HFOSC0_CLKOUT_32K_CTRL_SYNC_DIS — HFOSC0_CLKOUT_32K Synchronize Deactivate This bit must be written 0. Field values (others are reserved): 1'b0 - NORMAL
  [6:0] HFOSC0_CLKOUT_32K_CTRL_HSDIV — HFOSC0_CLKOUT_32K divider: HFOSC0_CLKKOUT_32K Frequency = HFOSC0 Frequency / [8 * (hsdiv + 1)] Ex. HFOSC0 Frequency = 26MHz. hsdiv = 101 (Default) HFOSC0_CLKOUT_32K = 26MHz / (8 * (101+1)) = 26MHz / 816 = 31.9 KHz
0x8038 CFG0_LFXOSC_CTRL reset 0x80
  [7] LFXOSC_CTRL_PD_C — Oscillator powerdown control. When set, oscillator is deactivated. Oscillator output is tristated if bp_c=0 Field values (others are reserved): 1'b0 - ACTIVE 1'b1 - POWERDOWN
  [4] LFXOSC_CTRL_BP_C — Oscillator bypass control. When set, oscillator is in bypass mode Field values (others are reserved): 1'b0 - ACTIVE 1'b1 - BYPASS
0x803C CFG0_LFXOSC_TRIM reset 0x121203
  [21:20] LFXOSC_TRIM_HYST — Sets comparator hysterisis Field values (others are reserved): 2'b00 - NO_HYS 2'b01 - TYPE1_HYS 2'b10 - TYPE2_HYS 2'b11 - BOTH_TYPES_HYS
  [18:16] LFXOSC_TRIM_I_MULT — AGC AMP current multiplication gain Field values (others are reserved): 3'b000 - AMP_AGC_IBIAS_3X 3'b001 - AMP_AGC_IBIAS_4X 3'b010 - AMP_AGC_IBIAS_5X 3'b011 - AMP_AGC_IBIAS_6X 3'b100 - AMP_AGC_IBIAS_7X 3'b101 - AMP_AGC_IBIAS_8X 3'b110 - AMP_AGC_IBIAS_9X 3'b111 - AMP_AGC_IBIAS_10X
  [13:8] LFXOSC_TRIM_R_REF — Sets the AMP AGC bias current Field values (others are reserved): 6'b000000 - OHMS_0K 6'b000001 - OHMS_24K 6'b000010 - OHMS_48K 6'b000011 - OHMS_73K 6'b000100 - OHMS_97K 6'b000101 - OHMS_121K 6'b000110 - OHMS_145K 6'b000111 - OHMS_169K 6'b001000 - OHMS_193K 6'b001001 - OHMS_218K 6'b001010 - OHMS_242K 6'b001011 - OHMS_266K 6'b001100 - OHMS_290K 6'b001101 - OHMS_314K 6'b001110 - OHMS_338K 6'b001111 - OHMS_363K 6'b010000 - OHMS_387K 6'b010001 - OHMS_411K 6'b010010 - OHMS_435K (Default) 6'b010011 - OHMS_459K 6'b010100 - OHMS_483K 6'b010101 - OHMS_508K 6'b010110 - OHMS_532K 6'b010111 - OHMS_556K 6'b011000 - OHMS_580K 6'b011001 - OHMS_604K 6'b011010 - OHMS_628K 6'b011011 - OHMS_653K 6'b011100 - OHMS_677K 6'b011101 - OHMS_701K 6'b011110 - OHMS_725K 6'b011111 - OHMS_749K 6'b100000 - OHMS_773K 6'b100001 - OHMS_798K 6'b100010 - OHMS_822K 6'b100011 - OHMS_846K 6'b100100 - OHMS_870K 6'b100101 - OHMS_894K 6'b100110 - OHMS_918K 6'b100111 - OHMS_943K 6'b101000 - OHMS_967K 6'b101001 - OHMS_991K 6'b101010 - OHMS_1015K 6'b101011 - OHMS_1039K 6'b101100 - OHMS_1063K 6'b101101 - OHMS_1088K 6'b101110 - OHMS_1112K 6'b101111 - OHMS_1136K 6'b110000 - OHMS_1160K 6'b110001 - OHMS_1184K 6'b110010 - OHMS_1208K 6'b110011 - OHMS_1233K 6'b110100 - OHMS_1257K 6'b110101 - OHMS_1281K 6'b110110 - OHMS_1305K 6'b110111 - OHMS_1329K 6'b111000 - OHMS_1353K 6'b111001 - OHMS_1378K 6'b111010 - OHMS_1402K 6'b111011 - OHMS_1426K 6'b111100 - OHMS_1450K 6'b111101 - OHMS_1474K 6'b111110 - OHMS_1498K 6'b111111 - OHMS_1523K
  [7:4] LFXOSC_TRIM_I_IBIAS_COMP — Sets the COMP bias current Field values (others are reserved): 4'b0000 - BASE_IBIAS_REF_X2 4'b0001 - BASE_IBIAS_REF_X3 4'b0010 - BASE_IBIAS_REF_X4 4'b0011 - BASE_IBIAS_REF_X5 4'b0100 - BASE_IBIAS_REF_X6 4'b0101 - BASE_IBIAS_REF_X7 4'b0110 - BASE_IBIAS_REF_X8 4'b0111 - BASE_IBIAS_REF_X9 4'b1000 - BASE_IBIAS_REF_X10 4'b1001 - BASE_IBIAS_REF_X11 4'b1010 - BASE_IBIAS_REF_X12 4'b1011 - BASE_IBIAS_REF_X13 4'b1100 - BASE_IBIAS_REF_X14 4'b1101 - BASE_IBIAS_REF_X15 4'b1110 - BASE_IBIAS_REF_X16 4'b1111 - BASE_IBIAS_REF_X17
  [3:0] LFXOSC_TRIM_R_IBIAS_REF — Sets the base IBIAS reference Field values (others are reserved): 4'b0000 - OHMS_512K 4'b0001 - OHMS_576K 4'b0010 - OHMS_640K 4'b0011 - OHMS_704K (Default) 4'b0100 - OHMS_768K 4'b0101 - OHMS_832K 4'b0110 - OHMS_896K 4'b0111 - OHMS_960K 4'b1000 - OHMS_1024K 4'b1001 - OHMS_1088K 4'b1010 - OHMS_1152K 4'b1011 - OHMS_1216K 4'b1100 - OHMS_1280K 4'b1101 - OHMS_1344K 4'b1110 - OHMS_1408K 4'b1111 - OHMS_1472K
